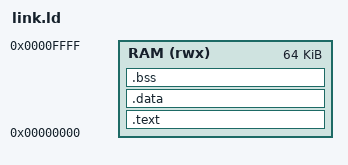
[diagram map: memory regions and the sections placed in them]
ENTRY(_start)

MEMORY
{
    RAM (rwx) : ORIGIN = 0x00000000, LENGTH = 64K
}

SECTIONS
{
    .text : {
        KEEP(*(.text.start))
        *(.text*)
        *(.rodata*)
        . = ALIGN(4);
    } > RAM

    .data : {
        *(.data*)
    } > RAM

    .bss (NOLOAD) : {
        . = ALIGN(4);
        __bss_start = .;
        *(.bss*)
        *(COMMON)
        . = ALIGN(4);
        __bss_end = .;
    } > RAM

    . = ALIGN(16);
    __image_end = .;
    __stack_top = ORIGIN(RAM) + LENGTH(RAM);

    /DISCARD/ : {
        *(.comment*)
        *(.eh_frame*)
    }
}

ASSERT(__image_end < __stack_top - 4096, "firmware leaves less than 4 KiB for stack")
